# ExynosT100 register map
Vendor: SAMSUNG System LSI; Series: ARMCM4F; File version: 0.1
CPU: CM4 r1p0, little endian, MPU, FPU, 3 interrupt priority bits
Registers are 32-bit, read-write, reset 0x0 unless marked. A register's access mark holds for its fields unless they carry their own. Offsets are from the block's base; [hi:lo] are bit positions; {n}, {i} and the like mark numbered series; 'fields as' and 'values as' point back to an identical list.

## ADC — Analog to Digiral Convertor
Base 0x400A0C00
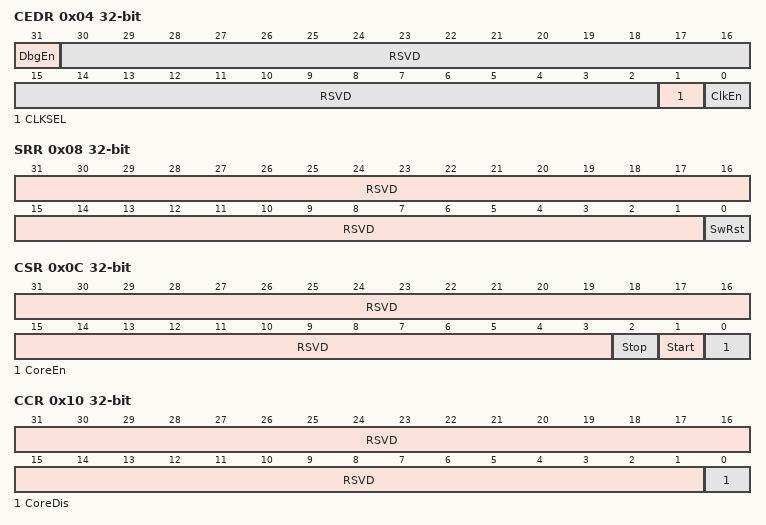
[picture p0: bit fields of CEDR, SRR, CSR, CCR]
0x04 CEDR — Clock Enable/Disable Register
  [31] DbgEn
  [30:2] RSVD ro
  [1] CLKSEL — ADC core clock selection bit 0 = DCXO clock 1 = System clock
  [0] ClkEn
0x08 SRR — Software Reset Register
  [31:1] RSVD ro, [0] SwRst wo
0x0C CSR — Control Set Register
  [31:3] RSVD ro
  [2] Stop wo — ADC conversion stops in continuous conversion This bit is auto-clear bit. 0 = No effect 1 = Stop the continuous conversion NOTE: Before starting conversion, you should ensure that ADC is ready for conversion (Busy status bit is set to logical 1 in SR).
  [1] Start wo — ADC conversion start bit 0 = No effect 1 = Start ADC conversion This is the one of ADC trigger sources and software trigger.
  [0] CoreEn wo — ADC enable bit 0 = No effect 1 = Enable ADC core Stable status bit in Status Register (SR) is set after stabilization
0x10 CCR — Control Clear Register
  [31:1] RSVD ro, [0] CoreDis wo
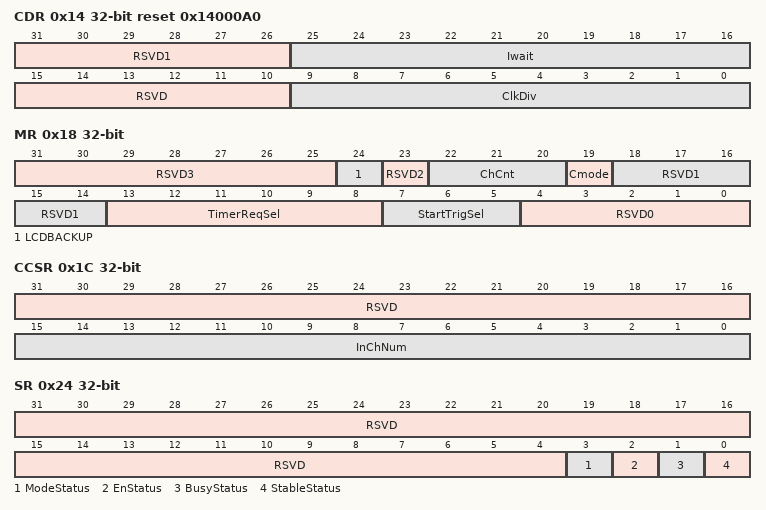
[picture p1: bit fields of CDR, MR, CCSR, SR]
0x14 CDR reset 0x14000A0 — Clock Divider Register
  [31:26] RSVD1 ro
  [25:16] Iwait — ADC stable time selection field This field can determine the ADC0 stable time and it is from 1 clk to 1024 clk. For example:: ADC CLK = 20 MHz, IWAIT= 20, and stable time = 1us
  [15:10] RSVD ro
  [9:0] ClkDiv
0x18 MR — Mode Register
  [31:25] RSVD3 ro
  [24] LCDBACKUP
  [23] RSVD2 ro
  [22:20] ChCnt — Conversion count field NOTE: Even in one shot mode, ADC runs multiple conversions if the ChCnt is greater than 000b and smaller than 011b. 000: One conversion operation of InChNum1 channel 001: Two times conversion operation from InChNum1 to InChNum2 010: Three times conversion operation from InChN1 to InChNum3 011: Four times conversion operation from InChNum1 to InChNum4
  [19] Cmode — Conversion mode control bit 0 = One shot mode. ADC converts max. inputs as specified by the ChCnt in the order specified in the MR and stops. 1 = Continuous mode. ADC converts max. inputs as specified by the ChCnt in the order specified in the MR and repeats. NOTE: In continuous mode, after a stop command, the ADC finishes the on-going conversion and this can be an extra conversion.
  [18:14] RSVD1 ro
  [13:8] TimerReqSel
  [7:5] StartTrigSel — ADC start trigger signal selection bits This field can determine the trigger signal for ADC. 000 = Software (Start bit in CSR) 100 = Timer/counter match Others = Reserved
  [4:0] RSVD0 ro
0x1C CCSR — Conversion Channel Sequence Register
  [31:16] RSVD ro
  [15:0] InChNum — Analog input channel number selection field Conversion sequence starts from first conversion channel defined by InChNum1[3:0] to last conversion channel defined by InChNum4[12:15]. InChNum Values Selected Pin 0000 Not selected 0001 ADC0 0010 ADC1 0011 ADC2 0100 ADC3
0x24 SR — Status Register
  [31:4] RSVD ro
  [3] ModeStatus ro — Continuous mode status 0 = One shot mode with help of microprocessor 1 = Continuous mode, the peripheral is stand-alone This bit is initialized to 0 and changes when there is a change of mode. This bit never generates any interruption.
  [2] EnStatus ro — ADC enable/disable status 0 = Disable 1 = Enable
  [1] BusyStatus ro — ADC status monitoring bit This bit can notify the status of ADC. 0 = ADC is not on a conversion operation 1 = ADC is on a conversion operation To change the configuration of ADC, you must check SR (ADC status register
  [0] StableStatus ro — ADC stabilization status 0 = ADC is not stabilized 1 = ADC is stabilized This bit is set after initialization time.
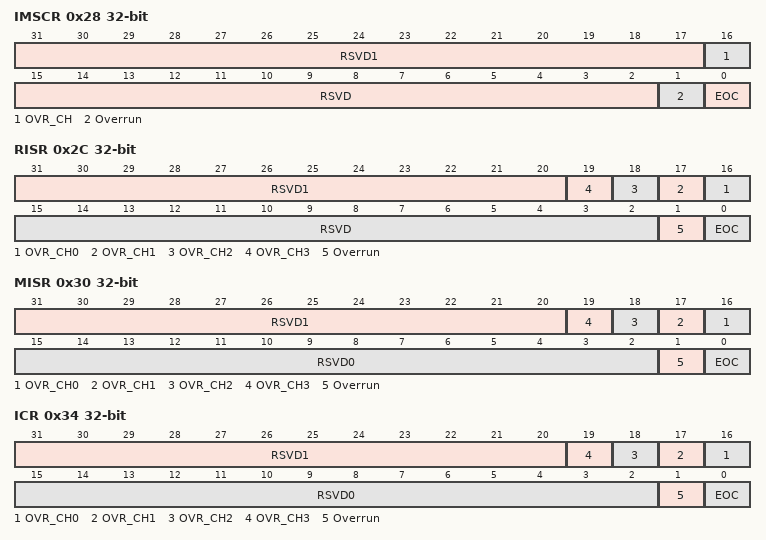
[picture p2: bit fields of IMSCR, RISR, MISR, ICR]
0x28 IMSCR — Interrupt Mask Set/Clear Register
  [31:17] RSVD1 ro
  [16] OVR_CH ro — Overrun interrupt mask for CH0, CH1, CH2, CH3 0 = OVR interrupt is masked (Disable the interrupt) 1 = OVR interrupt is not masked (Enable the interrupt)
  [15:2] RSVD ro
  [1] Overrun
  [0] EOC — End of conversion interrupt mask 0 = EOC interrupt is masked (Disable the interrupt) 1 = EOC interrupt is not masked (Enable the interrupt)
0x2C RISR — Interrupt Mask Set/Clear Register
  [31:20] RSVD1 ro
  [n+16] OVR_CH{n} ro (n=0..3) — Overrun raw interrupt status for CH{n} Gives the raw interrupt state (prior to masking) of the OVR interrupt
  [15:2] RSVD ro
  [1] Overrun ro
  [0] EOC ro — End of conversion interrupt mask 0 = EOC interrupt is masked (Disable the interrupt) 1 = EOC interrupt is not masked (Enable the interrupt)
0x30 MISR — Interrupt Mask Set/Clear Register
  [31:20] RSVD1 ro
  [n+16] OVR_CH{n} ro (n=0..3) — Overrun raw interrupt status for CH{n} Gives the raw interrupt state (prior to masking) of the OVR interrupt
  [15:2] RSVD0 ro
  [1] Overrun ro
  [0] EOC ro — End of conversion interrupt mask 0 = EOC interrupt is masked (Disable the interrupt) 1 = EOC interrupt is not masked (Enable the interrupt)
0x34 ICR — Overrun interrupt 0 = No effect 1 = Clears the overrun interrupt
  [31:20] RSVD1 wo, [n+16] OVR_CH{n} wo (n=0..3), [15:2] RSVD0 ro, [1] Overrun wo, [0] EOC wo
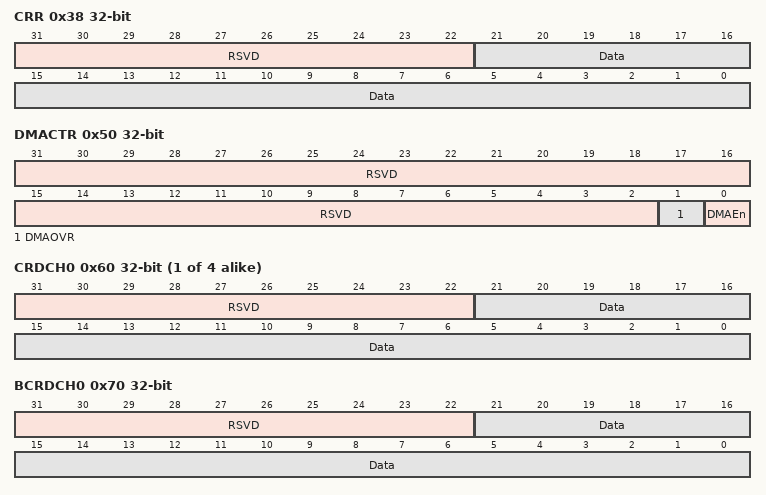
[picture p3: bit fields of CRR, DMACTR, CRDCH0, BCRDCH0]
0x38 CRR — Conversion Result Register
  [31:22] RSVD ro
  [21:0] Data ro — Conversion result data of ADC A/D converter output data result:upto 0x3FFFFF When A/D conversion is completed, the conversion result is read from the CRR register. The conversion data register should be read after the conversion is completed, EOC bit. NOTES: 1. ADC result value, without decimation, is set from bit [11] to [21]. 2. About ADC Result Data, please refer to chapter 1.2.2.1
0x50 DMACTR — DMA Control Register
  [31:2] RSVD ro
  [1] DMAOVR — DMA request stops at over run 0 = Disable 1 = Enable
  [0] DMAEn — DMA for ADC enable/disable control bit 0 = Disable 1 = Enable
{0x60+4i} CRDCH{i} (i=0..3) — Conversion Result Register of Ain{i}
  [31:22] RSVD ro
  [21:0] Data — Conversion result data of ADC A/D converter output channel data result:upto 0x3FFFFF When A/D conversion is completed, the conversion result is read from the CRR register. The conversion data register should be read after the conversion is completed, EOC bit.
0x70 BCRDCH0 — Backup of CRDCH0
  fields as CRDCH0
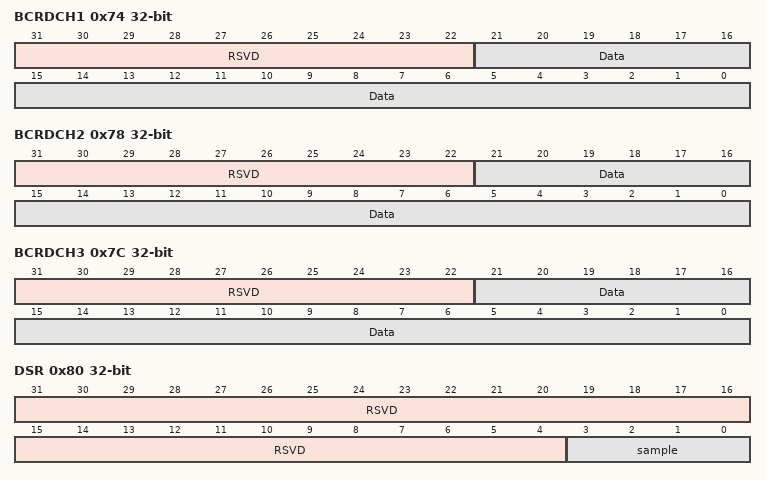
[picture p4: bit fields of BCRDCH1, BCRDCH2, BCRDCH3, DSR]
0x74 BCRDCH1 — Backup of CRDCH1
  [31:22] RSVD ro
  [21:0] Data — Conversion result data of ADC A/D converter output channel data result: upto 0x3FFFFF When A/D conversion is completed, the conversion result is read from the CRR register. The conversion data register should be read after the conversion is completed, EOC bit.
0x78 BCRDCH2 — Backup of CRDCH2
  fields as BCRDCH1
0x7C BCRDCH3 — Backup of CRDCH3
  [31:22] RSVD ro
  [21:0] Data — Conversion result data of ADC A/D converter output channel data result upto 0x3FFFFF When A/D conversion is completed, the conversion result is read from the CRR register. The conversion data register should be read after the conversion is completed, EOC bit.
0x80 DSR — Decimation Sampling Register
  [31:4] RSVD ro
  [3:0] sample — Decimation filter sampling data selection 2^n
